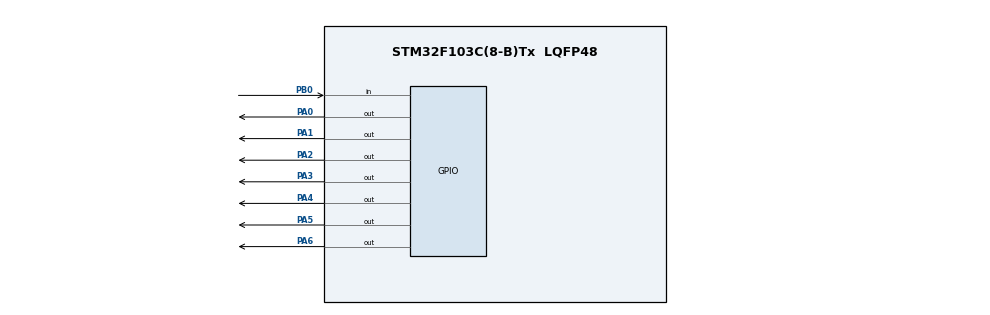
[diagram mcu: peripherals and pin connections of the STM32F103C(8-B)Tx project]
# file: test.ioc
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Mcu.Family=STM32F1
Mcu.Name=STM32F103C(8-B)Tx
Mcu.Package=LQFP48
NVIC.PriorityGroup=NVIC_PRIORITYGROUP_4
PA0-WKUP.Signal=GPIO_Output
PA1.Signal=GPIO_Output
PA13.Mode=Serial_Wire
PA13.Signal=SYS_JTMS-SWDIO
PA14.Mode=Serial_Wire
PA14.Signal=SYS_JTCK-SWCLK
PA2.Signal=GPIO_Output
PA3.Signal=GPIO_Output
PA4.Signal=GPIO_Output
PA5.Signal=GPIO_Output
PA6.Signal=GPIO_Output
PB0.GPIO_PuPd=GPIO_PULLUP
PB0.Signal=GPIO_Input
PD0-OSC_IN.Mode=HSE-External-Oscillator
PD0-OSC_IN.Signal=RCC_OSC_IN
PD1-OSC_OUT.Mode=HSE-External-Oscillator
PD1-OSC_OUT.Signal=RCC_OSC_OUT
ProjectManager.HeapSize=0x200
ProjectManager.StackSize=0x400
ProjectManager.TargetToolchain=Makefile
RCC.APB1Freq_Value=8000000
RCC.APB2Freq_Value=8000000
board=custom

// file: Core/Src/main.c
/* USER CODE BEGIN Header */
/**
 ******************************************************************************
 * @file           : main.c
 * @brief          : Main program body
 ******************************************************************************
 * @attention
 *
 * Copyright (c) 2022 STMicroelectronics.
 * All rights reserved.
 *
 * This software is licensed under terms that can be found in the LICENSE file
 * in the root directory of this software component.
 * If no LICENSE file comes with this software, it is provided AS-IS.
 *
 ******************************************************************************
 */
/* USER CODE END Header */
#include "main.h"
#include "gpio.h"

/* USER CODE BEGIN PV */
uint8_t code[] = {0x3f, 0x06, 0x5b, 0x40, 0x66, 0x6d, 0x7d, 0x07, 0x7f, 0x6f};
int count = 0;
/* USER CODE END PV */

void SystemClock_Config(void);

int main(void)
{

  /* MCU Configuration--------------------------------------------------------*/

  /* Reset of all peripherals, Initializes the Flash interface and the Systick. */
  HAL_Init();

  /* Configure the system clock */
  SystemClock_Config();

  /* Initialize all configured peripherals */
  MX_GPIO_Init();

  /* Infinite loop */
  while (1)
  {

    /* USER CODE BEGIN 3 */
    if (!HAL_GPIO_ReadPin(GPIOB, GPIO_PIN_0))
    {
      if (HAL_GPIO_ReadPin(GPIOB, GPIO_PIN_0))
      {
        GPIOA->ODR = code[count];
        count++;
        if (count == 9)
          count = 0;
      }
    }
  }
  /* USER CODE END 3 */
}

void SystemClock_Config(void)
{
  RCC_OscInitTypeDef RCC_OscInitStruct = {0};
  RCC_ClkInitTypeDef RCC_ClkInitStruct = {0};

  /** Initializes the RCC Oscillators according to the specified parameters
   * in the RCC_OscInitTypeDef structure.
   */
  RCC_OscInitStruct.OscillatorType = RCC_OSCILLATORTYPE_HSI;
  RCC_OscInitStruct.HSIState = RCC_HSI_ON;
  RCC_OscInitStruct.HSICalibrationValue = RCC_HSICALIBRATION_DEFAULT;
  RCC_OscInitStruct.PLL.PLLState = RCC_PLL_NONE;
  if (HAL_RCC_OscConfig(&RCC_OscInitStruct) != HAL_OK)
  {
    Error_Handler();
  }

  /** Initializes the CPU, AHB and APB buses clocks
   */
  RCC_ClkInitStruct.ClockType = RCC_CLOCKTYPE_HCLK | RCC_CLOCKTYPE_SYSCLK | RCC_CLOCKTYPE_PCLK1 | RCC_CLOCKTYPE_PCLK2;
  RCC_ClkInitStruct.SYSCLKSource = RCC_SYSCLKSOURCE_HSI;
  RCC_ClkInitStruct.AHBCLKDivider = RCC_SYSCLK_DIV1;
  RCC_ClkInitStruct.APB1CLKDivider = RCC_HCLK_DIV1;
  RCC_ClkInitStruct.APB2CLKDivider = RCC_HCLK_DIV1;

  if (HAL_RCC_ClockConfig(&RCC_ClkInitStruct, FLASH_LATENCY_0) != HAL_OK)
  {
    Error_Handler();
  }
}

void Error_Handler(void)
{
  __disable_irq();
  while (1)
  {
  }
}
